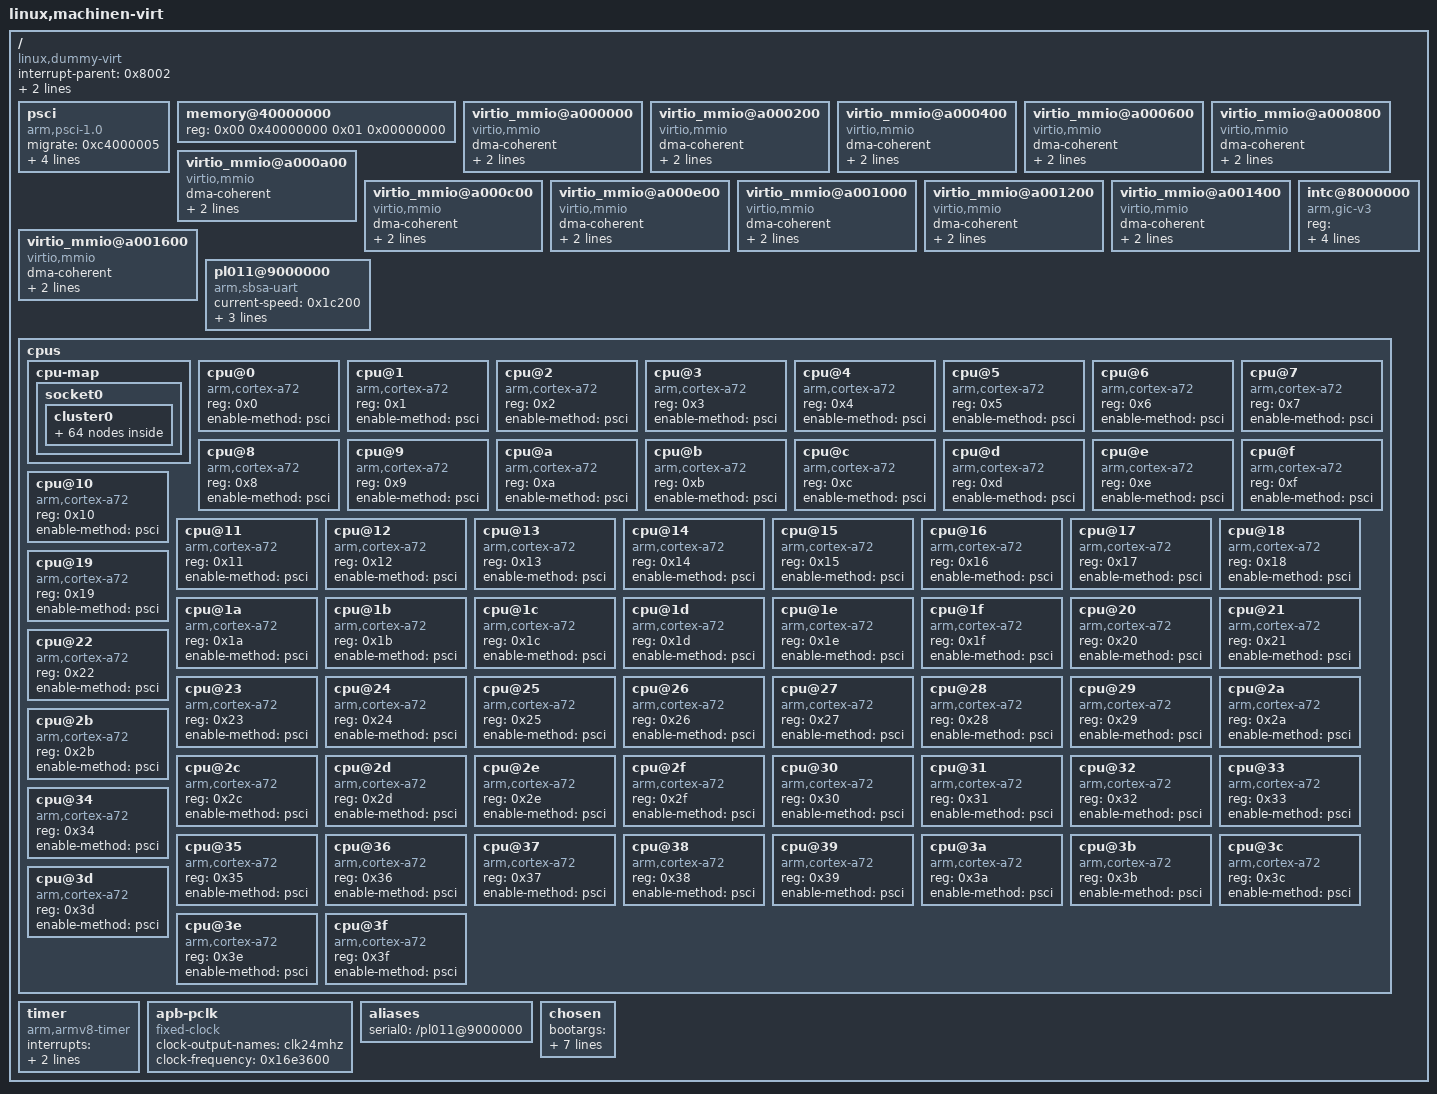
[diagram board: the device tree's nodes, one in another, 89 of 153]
/dts-v1/;

// Minimal arm64 "virt"-style device tree — trimmed for fast boot.
//
// What stays in is what the guest kernel + our VMM actually touch:
//   * the GIC v3 (interrupt controller — required)
//   * PL011 UART at 0x9000000 (console)
//   * twelve virtio-mmio slots at 0x0a000000+i*0x200:
//       0=net, 1=blk (rootdisk), 2=vsock, 3=blk2 (scratch),
//       4=balloon, 5=blk3 (mount lower / squashfs RO),
//       6=blk4 (mount upper / ext4 RW),
//       7..11=virtio-fs (#332 live mount, up to 5 per VM — #338)
//   * CPU, timer, psci, apb-pclk
//
// Slot 1 (blk) and slot 3 (blk2) carry the two virtio-blk devices:
// rootdisk on slot 1 (becomes /dev/vda) and scratch on slot 3
// (/dev/vdb when both are present). The runtime feeds them via
// MACHINEN_ROOTDISK and MACHINEN_DISK respectively. See #114.
//
// Slots 5 (blk3) and 6 (blk4) carry the `--mount` payload (#272):
// a content-addressed squashfs lower (RO) and a per-VM ext4 upper
// (RW), layered into a single overlayfs at /mnt/<guest>/ by /init.
// They become /dev/vdc and /dev/vdd in DTB order when rootdisk +
// scratch are both populated. The runtime feeds them via
// MACHINEN_MOUNTDISK_LOWER_FD and MACHINEN_MOUNTDISK_UPPER_FD —
// fd-passed, never path-passed, so the host source dir is never
// consulted by the guest at runtime.
//
// Nodes we *used* to carry via the QEMU virt reference DTS and have
// now dropped for sub-second-spawn work (#50): `pcie`, `pl031` rtc,
// `pmu`, `flash`, `fw-cfg`, `platform-bus`, `gpio-keys`/`pl061`, the
// GIC ITS, and 28 unused virtio_mmio slots. Each of these made the
// kernel spend time probing things we never use.

/ {
	interrupt-parent = <0x8002>;
	dma-coherent;
	model = "linux,machinen-virt";
	#size-cells = <0x02>;
	#address-cells = <0x02>;
	compatible = "linux,dummy-virt";

	psci {
		migrate = <0xc4000005>;
		cpu_on = <0xc4000003>;
		cpu_off = <0x84000002>;
		cpu_suspend = <0xc4000001>;
		method = "hvc";
		compatible = "arm,psci-1.0", "arm,psci-0.2", "arm,psci";
	};

	memory@40000000 {
		reg = <0x00 0x40000000 0x01 0x00000000>;
		device_type = "memory";
	};

	virtio_mmio@a000000 {
		dma-coherent;
		interrupts = <0x00 0x10 0x01>;
		reg = <0x00 0xa000000 0x00 0x200>;
		compatible = "virtio,mmio";
	};

	virtio_mmio@a000200 {
		dma-coherent;
		interrupts = <0x00 0x11 0x01>;
		reg = <0x00 0xa000200 0x00 0x200>;
		compatible = "virtio,mmio";
	};

	virtio_mmio@a000400 {
		dma-coherent;
		interrupts = <0x00 0x12 0x01>;
		reg = <0x00 0xa000400 0x00 0x200>;
		compatible = "virtio,mmio";
	};

	virtio_mmio@a000600 {
		dma-coherent;
		interrupts = <0x00 0x13 0x01>;
		reg = <0x00 0xa000600 0x00 0x200>;
		compatible = "virtio,mmio";
	};

	// #263 phase B: slot 4 carries virtio-balloon. The driver posts
	// free-page batches on the page-reporting virtqueue; the host
	// madvises(MADV_DONTNEED) the corresponding range so RSS shrinks
	// alongside guest free memory.
	virtio_mmio@a000800 {
		dma-coherent;
		interrupts = <0x00 0x14 0x01>;
		reg = <0x00 0xa000800 0x00 0x200>;
		compatible = "virtio,mmio";
	};

	// #272: slot 5 carries the squashfs RO lower for the `--mount`
	// payload. The runtime fd-passes the content-addressed cache
	// file via MACHINEN_MOUNTDISK_LOWER_FD; /init mounts the
	// resulting /dev/vdc read-only at a pre-pivot path.
	virtio_mmio@a000a00 {
		dma-coherent;
		interrupts = <0x00 0x15 0x01>;
		reg = <0x00 0xa000a00 0x00 0x200>;
		compatible = "virtio,mmio";
	};

	// #272: slot 6 carries the ext4 RW upper for the `--mount`
	// overlay. Per-VM sparse file fd-passed via
	// MACHINEN_MOUNTDISK_UPPER_FD; /init mounts /dev/vdd with
	// `discard` so deletes auto-reclaim host disk via virtio-blk
	// VIRTIO_BLK_F_DISCARD → fallocate(PUNCH_HOLE).
	virtio_mmio@a000c00 {
		dma-coherent;
		interrupts = <0x00 0x16 0x01>;
		reg = <0x00 0xa000c00 0x00 0x200>;
		compatible = "virtio,mmio";
	};

	// #332/#338: slots 7..11 carry up to five virtio-fs devices, one
	// per `--mount-live` (and one is consumed internally by a
	// `restore({ lazy: true })` to serve the page image). Each in-VMM
	// device serves a host directory over a FUSE-derived virtqueue
	// protocol; /init mounts it with `mount -t virtiofs <tag> <guest>`.
	// Replaces the FUSE-over-vsock transport — no vsock framing, no
	// guest fuse-agent byte-pump. A slot is empty when the runtime
	// didn't request that many live mounts.
	virtio_mmio@a000e00 {
		dma-coherent;
		interrupts = <0x00 0x17 0x01>;
		reg = <0x00 0xa000e00 0x00 0x200>;
		compatible = "virtio,mmio";
	};

	virtio_mmio@a001000 {
		dma-coherent;
		interrupts = <0x00 0x18 0x01>;
		reg = <0x00 0xa001000 0x00 0x200>;
		compatible = "virtio,mmio";
	};

	virtio_mmio@a001200 {
		dma-coherent;
		interrupts = <0x00 0x19 0x01>;
		reg = <0x00 0xa001200 0x00 0x200>;
		compatible = "virtio,mmio";
	};

	virtio_mmio@a001400 {
		dma-coherent;
		interrupts = <0x00 0x1a 0x01>;
		reg = <0x00 0xa001400 0x00 0x200>;
		compatible = "virtio,mmio";
	};

	virtio_mmio@a001600 {
		dma-coherent;
		interrupts = <0x00 0x1b 0x01>;
		reg = <0x00 0xa001600 0x00 0x200>;
		compatible = "virtio,mmio";
	};

	pl011@9000000 {
		current-speed = <0x1c200>;  // 115200
		clock-names = "uartclk", "apb_pclk";
		clocks = <0x8000 0x8000>;
		interrupts = <0x00 0x01 0x04>;
		reg = <0x00 0x9000000 0x00 0x1000>;
		compatible = "arm,sbsa-uart";
	};

	intc@8000000 {
		phandle = <0x8002>;
		reg = <0x00 0x8000000 0x00 0x10000 0x00 0x10000000 0x00 0x2000000>;
		// VGIC maintenance PPI (INTID 25 / PPI 9). Needed when EL2 is
		// exposed to the guest so its in-guest KVM can receive virtual
		// interrupt maintenance events.
		interrupts = <0x01 0x09 0x04>;
		#redistributor-regions = <0x01>;
		compatible = "arm,gic-v3";
		ranges;
		#size-cells = <0x02>;
		#address-cells = <0x02>;
		interrupt-controller;
		#interrupt-cells = <0x03>;
	};

	cpus {
		#size-cells = <0x00>;
		#address-cells = <0x01>;

		cpu-map {
			socket0 {
				cluster0 {
					core0 {
						cpu = <0x8100>;
					};
					core1 {
						cpu = <0x8101>;
					};
					core2 {
						cpu = <0x8102>;
					};
					core3 {
						cpu = <0x8103>;
					};
					core4 {
						cpu = <0x8104>;
					};
					core5 {
						cpu = <0x8105>;
					};
					core6 {
						cpu = <0x8106>;
					};
					core7 {
						cpu = <0x8107>;
					};
					core8 {
						cpu = <0x8108>;
					};
					core9 {
						cpu = <0x8109>;
					};
					core10 {
						cpu = <0x810a>;
					};
					core11 {
						cpu = <0x810b>;
					};
					core12 {
						cpu = <0x810c>;
					};
					core13 {
						cpu = <0x810d>;
					};
					core14 {
						cpu = <0x810e>;
					};
					core15 {
						cpu = <0x810f>;
					};
					core16 {
						cpu = <0x8110>;
					};
					core17 {
						cpu = <0x8111>;
					};
					core18 {
						cpu = <0x8112>;
					};
					core19 {
						cpu = <0x8113>;
					};
					core20 {
						cpu = <0x8114>;
					};
					core21 {
						cpu = <0x8115>;
					};
					core22 {
						cpu = <0x8116>;
					};
					core23 {
						cpu = <0x8117>;
					};
					core24 {
						cpu = <0x8118>;
					};
					core25 {
						cpu = <0x8119>;
					};
					core26 {
						cpu = <0x811a>;
					};
					core27 {
						cpu = <0x811b>;
					};
					core28 {
						cpu = <0x811c>;
					};
					core29 {
						cpu = <0x811d>;
					};
					core30 {
						cpu = <0x811e>;
					};
					core31 {
						cpu = <0x811f>;
					};
					core32 {
						cpu = <0x8120>;
					};
					core33 {
						cpu = <0x8121>;
					};
					core34 {
						cpu = <0x8122>;
					};
					core35 {
						cpu = <0x8123>;
					};
					core36 {
						cpu = <0x8124>;
					};
					core37 {
						cpu = <0x8125>;
					};
					core38 {
						cpu = <0x8126>;
					};
					core39 {
						cpu = <0x8127>;
					};
					core40 {
						cpu = <0x8128>;
					};
					core41 {
						cpu = <0x8129>;
					};
					core42 {
						cpu = <0x812a>;
					};
					core43 {
						cpu = <0x812b>;
					};
					core44 {
						cpu = <0x812c>;
					};
					core45 {
						cpu = <0x812d>;
					};
					core46 {
						cpu = <0x812e>;
					};
					core47 {
						cpu = <0x812f>;
					};
					core48 {
						cpu = <0x8130>;
					};
					core49 {
						cpu = <0x8131>;
					};
					core50 {
						cpu = <0x8132>;
					};
					core51 {
						cpu = <0x8133>;
					};
					core52 {
						cpu = <0x8134>;
					};
					core53 {
						cpu = <0x8135>;
					};
					core54 {
						cpu = <0x8136>;
					};
					core55 {
						cpu = <0x8137>;
					};
					core56 {
						cpu = <0x8138>;
					};
					core57 {
						cpu = <0x8139>;
					};
					core58 {
						cpu = <0x813a>;
					};
					core59 {
						cpu = <0x813b>;
					};
					core60 {
						cpu = <0x813c>;
					};
					core61 {
						cpu = <0x813d>;
					};
					core62 {
						cpu = <0x813e>;
					};
					core63 {
						cpu = <0x813f>;
					};
				};
			};
		};

		cpu@0 {
			phandle = <0x8100>;
			reg = <0x0>;
			compatible = "arm,cortex-a72";
			device_type = "cpu";
			enable-method = "psci";
		};

		cpu@1 {
			phandle = <0x8101>;
			reg = <0x1>;
			compatible = "arm,cortex-a72";
			device_type = "cpu";
			enable-method = "psci";
		};

		cpu@2 {
			phandle = <0x8102>;
			reg = <0x2>;
			compatible = "arm,cortex-a72";
			device_type = "cpu";
			enable-method = "psci";
		};

		cpu@3 {
			phandle = <0x8103>;
			reg = <0x3>;
			compatible = "arm,cortex-a72";
			device_type = "cpu";
			enable-method = "psci";
		};

		cpu@4 {
			phandle = <0x8104>;
			reg = <0x4>;
			compatible = "arm,cortex-a72";
			device_type = "cpu";
			enable-method = "psci";
		};

		cpu@5 {
			phandle = <0x8105>;
			reg = <0x5>;
			compatible = "arm,cortex-a72";
			device_type = "cpu";
			enable-method = "psci";
		};

		cpu@6 {
			phandle = <0x8106>;
			reg = <0x6>;
			compatible = "arm,cortex-a72";
			device_type = "cpu";
			enable-method = "psci";
		};

		cpu@7 {
			phandle = <0x8107>;
			reg = <0x7>;
			compatible = "arm,cortex-a72";
			device_type = "cpu";
			enable-method = "psci";
		};

		cpu@8 {
			phandle = <0x8108>;
			reg = <0x8>;
			compatible = "arm,cortex-a72";
			device_type = "cpu";
			enable-method = "psci";
		};

		cpu@9 {
			phandle = <0x8109>;
			reg = <0x9>;
			compatible = "arm,cortex-a72";
			device_type = "cpu";
			enable-method = "psci";
		};

		cpu@a {
			phandle = <0x810a>;
			reg = <0xa>;
			compatible = "arm,cortex-a72";
			device_type = "cpu";
			enable-method = "psci";
		};

		cpu@b {
			phandle = <0x810b>;
			reg = <0xb>;
			compatible = "arm,cortex-a72";
			device_type = "cpu";
			enable-method = "psci";
		};

		cpu@c {
			phandle = <0x810c>;
			reg = <0xc>;
			compatible = "arm,cortex-a72";
			device_type = "cpu";
			enable-method = "psci";
		};

		cpu@d {
			phandle = <0x810d>;
			reg = <0xd>;
			compatible = "arm,cortex-a72";
			device_type = "cpu";
			enable-method = "psci";
		};

		cpu@e {
			phandle = <0x810e>;
			reg = <0xe>;
			compatible = "arm,cortex-a72";
			device_type = "cpu";
			enable-method = "psci";
		};

		cpu@f {
			phandle = <0x810f>;
			reg = <0xf>;
			compatible = "arm,cortex-a72";
			device_type = "cpu";
			enable-method = "psci";
		};

		cpu@10 {
			phandle = <0x8110>;
			reg = <0x10>;
			compatible = "arm,cortex-a72";
			device_type = "cpu";
			enable-method = "psci";
		};

		cpu@11 {
			phandle = <0x8111>;
			reg = <0x11>;
			compatible = "arm,cortex-a72";
			device_type = "cpu";
			enable-method = "psci";
		};

		cpu@12 {
			phandle = <0x8112>;
			reg = <0x12>;
			compatible = "arm,cortex-a72";
			device_type = "cpu";
			enable-method = "psci";
		};

		cpu@13 {
			phandle = <0x8113>;
			reg = <0x13>;
			compatible = "arm,cortex-a72";
			device_type = "cpu";
			enable-method = "psci";
		};

		cpu@14 {
			phandle = <0x8114>;
			reg = <0x14>;
			compatible = "arm,cortex-a72";
			device_type = "cpu";
			enable-method = "psci";
		};

		cpu@15 {
			phandle = <0x8115>;
			reg = <0x15>;
			compatible = "arm,cortex-a72";
			device_type = "cpu";
			enable-method = "psci";
		};

		cpu@16 {
			phandle = <0x8116>;
			reg = <0x16>;
			compatible = "arm,cortex-a72";
			device_type = "cpu";
			enable-method = "psci";
		};

		cpu@17 {
			phandle = <0x8117>;
			reg = <0x17>;
			compatible = "arm,cortex-a72";
			device_type = "cpu";
			enable-method = "psci";
		};

		cpu@18 {
			phandle = <0x8118>;
			reg = <0x18>;
			compatible = "arm,cortex-a72";
			device_type = "cpu";
			enable-method = "psci";
		};

		cpu@19 {
			phandle = <0x8119>;
			reg = <0x19>;
			compatible = "arm,cortex-a72";
			device_type = "cpu";
			enable-method = "psci";
		};

		cpu@1a {
			phandle = <0x811a>;
			reg = <0x1a>;
			compatible = "arm,cortex-a72";
			device_type = "cpu";
			enable-method = "psci";
		};

		cpu@1b {
			phandle = <0x811b>;
			reg = <0x1b>;
			compatible = "arm,cortex-a72";
			device_type = "cpu";
			enable-method = "psci";
		};

		cpu@1c {
			phandle = <0x811c>;
			reg = <0x1c>;
			compatible = "arm,cortex-a72";
			device_type = "cpu";
			enable-method = "psci";
		};

		cpu@1d {
			phandle = <0x811d>;
			reg = <0x1d>;
			compatible = "arm,cortex-a72";
			device_type = "cpu";
			enable-method = "psci";
		};

		cpu@1e {
			phandle = <0x811e>;
			reg = <0x1e>;
			compatible = "arm,cortex-a72";
			device_type = "cpu";
			enable-method = "psci";
		};

		cpu@1f {
			phandle = <0x811f>;
			reg = <0x1f>;
			compatible = "arm,cortex-a72";
			device_type = "cpu";
			enable-method = "psci";
		};

		cpu@20 {
			phandle = <0x8120>;
			reg = <0x20>;
			compatible = "arm,cortex-a72";
			device_type = "cpu";
			enable-method = "psci";
		};

		cpu@21 {
			phandle = <0x8121>;
			reg = <0x21>;
			compatible = "arm,cortex-a72";
			device_type = "cpu";
			enable-method = "psci";
		};

		cpu@22 {
			phandle = <0x8122>;
			reg = <0x22>;
			compatible = "arm,cortex-a72";
			device_type = "cpu";
			enable-method = "psci";
		};

		cpu@23 {
			phandle = <0x8123>;
			reg = <0x23>;
			compatible = "arm,cortex-a72";
			device_type = "cpu";
			enable-method = "psci";
		};

		cpu@24 {
			phandle = <0x8124>;
			reg = <0x24>;
			compatible = "arm,cortex-a72";
			device_type = "cpu";
			enable-method = "psci";
		};

		cpu@25 {
			phandle = <0x8125>;
			reg = <0x25>;
			compatible = "arm,cortex-a72";
			device_type = "cpu";
			enable-method = "psci";
		};

		cpu@26 {
			phandle = <0x8126>;
			reg = <0x26>;
			compatible = "arm,cortex-a72";
			device_type = "cpu";
			enable-method = "psci";
		};

		cpu@27 {
			phandle = <0x8127>;
			reg = <0x27>;
			compatible = "arm,cortex-a72";
			device_type = "cpu";
			enable-method = "psci";
		};

		cpu@28 {
			phandle = <0x8128>;
			reg = <0x28>;
			compatible = "arm,cortex-a72";
			device_type = "cpu";
			enable-method = "psci";
		};

		cpu@29 {
			phandle = <0x8129>;
			reg = <0x29>;
			compatible = "arm,cortex-a72";
			device_type = "cpu";
			enable-method = "psci";
		};

		cpu@2a {
			phandle = <0x812a>;
			reg = <0x2a>;
			compatible = "arm,cortex-a72";
			device_type = "cpu";
			enable-method = "psci";
		};

		cpu@2b {
			phandle = <0x812b>;
			reg = <0x2b>;
			compatible = "arm,cortex-a72";
			device_type = "cpu";
			enable-method = "psci";
		};

		cpu@2c {
			phandle = <0x812c>;
			reg = <0x2c>;
			compatible = "arm,cortex-a72";
			device_type = "cpu";
			enable-method = "psci";
		};

		cpu@2d {
			phandle = <0x812d>;
			reg = <0x2d>;
			compatible = "arm,cortex-a72";
			device_type = "cpu";
			enable-method = "psci";
		};

		cpu@2e {
			phandle = <0x812e>;
			reg = <0x2e>;
			compatible = "arm,cortex-a72";
			device_type = "cpu";
			enable-method = "psci";
		};

		cpu@2f {
			phandle = <0x812f>;
			reg = <0x2f>;
			compatible = "arm,cortex-a72";
			device_type = "cpu";
			enable-method = "psci";
		};

		cpu@30 {
			phandle = <0x8130>;
			reg = <0x30>;
			compatible = "arm,cortex-a72";
			device_type = "cpu";
			enable-method = "psci";
		};

		cpu@31 {
			phandle = <0x8131>;
			reg = <0x31>;
			compatible = "arm,cortex-a72";
			device_type = "cpu";
			enable-method = "psci";
		};

		cpu@32 {
			phandle = <0x8132>;
			reg = <0x32>;
			compatible = "arm,cortex-a72";
			device_type = "cpu";
			enable-method = "psci";
		};

		cpu@33 {
			phandle = <0x8133>;
			reg = <0x33>;
			compatible = "arm,cortex-a72";
			device_type = "cpu";
			enable-method = "psci";
		};

		cpu@34 {
			phandle = <0x8134>;
			reg = <0x34>;
			compatible = "arm,cortex-a72";
			device_type = "cpu";
			enable-method = "psci";
		};

		cpu@35 {
			phandle = <0x8135>;
			reg = <0x35>;
			compatible = "arm,cortex-a72";
			device_type = "cpu";
			enable-method = "psci";
		};

		cpu@36 {
			phandle = <0x8136>;
			reg = <0x36>;
			compatible = "arm,cortex-a72";
			device_type = "cpu";
			enable-method = "psci";
		};

		cpu@37 {
			phandle = <0x8137>;
			reg = <0x37>;
			compatible = "arm,cortex-a72";
			device_type = "cpu";
			enable-method = "psci";
		};

		cpu@38 {
			phandle = <0x8138>;
			reg = <0x38>;
			compatible = "arm,cortex-a72";
			device_type = "cpu";
			enable-method = "psci";
		};

		cpu@39 {
			phandle = <0x8139>;
			reg = <0x39>;
			compatible = "arm,cortex-a72";
			device_type = "cpu";
			enable-method = "psci";
		};

		cpu@3a {
			phandle = <0x813a>;
			reg = <0x3a>;
			compatible = "arm,cortex-a72";
			device_type = "cpu";
			enable-method = "psci";
		};

		cpu@3b {
			phandle = <0x813b>;
			reg = <0x3b>;
			compatible = "arm,cortex-a72";
			device_type = "cpu";
			enable-method = "psci";
		};

		cpu@3c {
			phandle = <0x813c>;
			reg = <0x3c>;
			compatible = "arm,cortex-a72";
			device_type = "cpu";
			enable-method = "psci";
		};

		cpu@3d {
			phandle = <0x813d>;
			reg = <0x3d>;
			compatible = "arm,cortex-a72";
			device_type = "cpu";
			enable-method = "psci";
		};

		cpu@3e {
			phandle = <0x813e>;
			reg = <0x3e>;
			compatible = "arm,cortex-a72";
			device_type = "cpu";
			enable-method = "psci";
		};

		cpu@3f {
			phandle = <0x813f>;
			reg = <0x3f>;
			compatible = "arm,cortex-a72";
			device_type = "cpu";
			enable-method = "psci";
		};
	};

	timer {
		interrupts = <0x01 0x0d 0x04 0x01 0x0e 0x04 0x01 0x0b 0x04 0x01 0x0a 0x04>;
		always-on;
		compatible = "arm,armv8-timer", "arm,armv7-timer";
	};

	apb-pclk {
		phandle = <0x8000>;
		clock-output-names = "clk24mhz";
		clock-frequency = <0x16e3600>;
		#clock-cells = <0x00>;
		compatible = "fixed-clock";
	};

	aliases {
		serial0 = "/pl011@9000000";
	};

	chosen {
		bootargs = "earlycon=pl011,mmio32,0x9000000 console=ttyAMA0 panic=1 loglevel=3 quiet arm64.nopauth arm64.nosve arm64.nosme";
		linux,initrd-start = <0x44000000>;
		// End of the initrd reserved region. The kernel scans the whole
		// window looking for concatenated cpio archives; leaving this
		// too generous costs real wall-clock during early boot (#50
		// sub-second spawn). Sized to fit the current full rootfs cpio
		// (~884 MB) with slack. TODO: patch at runtime from the actual
		// loaded initrd length so slim cpios get the full win.
		linux,initrd-end = <0x84000000>;
		stdout-path = "/pl011@9000000";
		rng-seed = <0x1a11afe9 0x8fd8244a 0xab34bc9d 0x722c6957 0xd0b2f2e0 0x82d58105 0x88b74715 0x107ef8a1>;
		kaslr-seed = <0xdb4642f7 0x8a825170>;
	};
};
